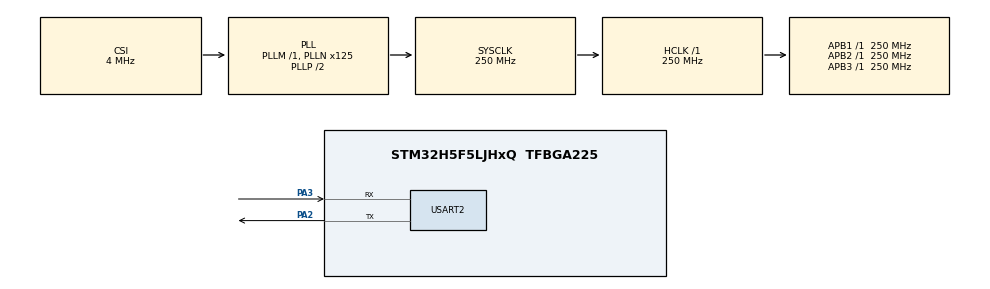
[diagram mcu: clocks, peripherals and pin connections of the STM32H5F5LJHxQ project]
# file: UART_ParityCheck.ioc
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CORTEX_M33_NS.userName=CORTEX_M33
Mcu.Family=STM32H5
Mcu.Name=STM32H5F5LJHxQ
Mcu.Package=TFBGA225
NVIC.PriorityGroup=NVIC_PRIORITYGROUP_4
NVIC.USART2_IRQn=true\:0\:0\:false\:false\:true\:true\:true\:true
PA2.Mode=Asynchronous
PA2.Signal=USART2_TX
PA3.Mode=Asynchronous
PA3.Signal=USART2_RX
ProjectManager.HeapSize=0x200
ProjectManager.StackSize=0x400
ProjectManager.TargetToolchain=EWARM V9.20
RCC.ADCFreq_Value=250000000
RCC.AHBFreq_Value=250000000
RCC.APB1Freq_Value=250000000
RCC.APB1TimFreq_Value=250000000
RCC.APB2Freq_Value=250000000
RCC.APB2TimFreq_Value=250000000
RCC.APB3Freq_Value=250000000
RCC.CSI_VALUE=4000000
RCC.CortexFreq_Value=250000000
RCC.EPOD_VALUE=4000000
RCC.HCLKFreq_Value=250000000
RCC.HSE_VALUE=25000000
RCC.HSI48_VALUE=48000000
RCC.HSI_VALUE=64000000
RCC.LSE_VALUE=32768
RCC.LSIRC_VALUE=32000
RCC.PLLN=125
RCC.SYSCLKFreq_VALUE=250000000
RCC.SYSCLKSource=RCC_SYSCLKSOURCE_PLLCLK
RCC.USBFreq_Value=258000000
RCC.VCOOutputFreq_Value=500000000
USART2.Parity=PARITY_ODD
USART2.VirtualMode-Asynchronous=VM_ASYNC
USART2.WordLength=WORDLENGTH_9B
VP_CORTEX_M33_NS_VS_Hclk.Mode=Hclk_Mode
VP_ICACHE_VS_ICACHE.Mode=DefaultMode
VP_PWR_VS_LPOM.Mode=PowerOptimisation
VP_PWR_VS_SECSignals.Mode=Security/Privilege
board=custom

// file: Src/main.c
/* USER CODE BEGIN Header */
/**
  ******************************************************************************
  * @file    UART/UART_ParityCheck/Src/main.c
  * @author  MCD Application Team
  * @brief   This example shows how to retarget the C library printf function
  *          to the UART.
  ******************************************************************************
  * @attention
  *
  * Copyright (c) 2023 STMicroelectronics.
  * All rights reserved.
  *
  * This software is licensed under terms that can be found in the LICENSE file
  * in the root directory of this software component.
  * If no LICENSE file comes with this software, it is provided AS-IS.
  *
  ******************************************************************************
  */
/* USER CODE END Header */
#include "main.h"

UART_HandleTypeDef huart2;

/* USER CODE BEGIN PV */
uint8_t aTxStartMessage[] = "\n\r ****UART-ParityCheck communication based on IT ****\n\r Enter 10 characters using keyboard :\n\r";
uint8_t aTxParityErrorMessage[] = "\n\r Parity error detected, parity is now set to even. Please retry sending 10 characters \n\r";
uint8_t aTxEndMessage[] = "\n\r No Parity error detected, end of example \n\r";

/* Buffer used for reception */
uint8_t aRxBuffer[RXBUFFERSIZE];

volatile uint8_t Parity_Error_Count = 0U;
volatile uint8_t TxCpltCallback = 0U;
volatile uint8_t RxCpltCallback = 0U;
/* USER CODE END PV */

void SystemClock_Config(void);
static void MX_GPIO_Init(void);
static void MX_ICACHE_Init(void);
static void MX_USART2_UART_Init(void);

int main(void)
{

  /* USER CODE BEGIN 1 */

  /* STM32H5xx HAL library initialization:
       - Systick timer is configured by default as source of time base, but user
             can eventually implement his proper time base source (a general purpose
             timer for example or other time source), keeping in mind that Time base
             duration should be kept 1ms since PPP_TIMEOUT_VALUEs are defined and
             handled in milliseconds basis.
       - Set NVIC Group Priority to 4
       - Low Level Initialization
     */
  /* USER CODE END 1 */

  /* MCU Configuration--------------------------------------------------------*/

  /* Reset of all peripherals, Initializes the Flash interface and the Systick. */
  HAL_Init();

  /* Configure the system clock */
  SystemClock_Config();

  /* USER CODE BEGIN SysInit */
  /* Initialize BSP Led for LED3 & LED1 */
  BSP_LED_Init(LED3);
  BSP_LED_Init(LED1);

  /* USER CODE END SysInit */

  /* Initialize all configured peripherals */
  MX_GPIO_Init();
  MX_ICACHE_Init();
  MX_USART2_UART_Init();
  /* USER CODE BEGIN 2 */

  /*##-1- Start the transmission process ######################################*/
  if(HAL_UART_Transmit_IT(&huart2, (uint8_t*)aTxStartMessage, TXSTARTMESSAGESIZE)!= HAL_OK)
  {
    /* Transfer error in transmission process */
    Error_Handler();
  }

  /*##-2- Wait for the end of the transfer ####################################*/
  /*  As the next step is to change the parity to create a parity error
      in the next reception, we need to make sure the last transfer ended
      before changing the configuration */
  while (TxCpltCallback == 0U)
  {
  }
  TxCpltCallback = 0U;

  /*##-3- Change Parity configuration to trigger a parity error ###############*/
  huart2.Init.Parity = UART_PARITY_EVEN;
  if (HAL_UART_Init(&huart2) != HAL_OK)
  {
    Error_Handler();
  }

  /*##-4- Put UART peripheral in reception process ############################*/
  /* Any data received will be stored in "aRxBuffer" buffer : the number max of
     data received is 10 */
  if(HAL_UART_Receive_IT(&huart2, (uint8_t *)aRxBuffer, RXBUFFERSIZE) != HAL_OK)
  {
    /* Transfer error in reception process */
    Error_Handler();
  }

  /*##-5- Wait for the end of the transfer ####################################*/
  /* After detecting a parity error the HAL_UART_ErrorCallback will update the
    private variable Parity_Error_Count to reflect the error status. This variable is
    then used in main to change the parity configuration once the reception is completed,
    thus we make sure to avoid starting the next transfer before the parity configuration change */
  while (RxCpltCallback == 0U)
  {
  }
  RxCpltCallback = 0U;

  /* Each character received triggers a parity error */
  if (Parity_Error_Count == RXBUFFERSIZE)
  {
    /* Parity error detected */
    BSP_LED_On(LED1);

    /*##-6- Change back parity configuration ##################################*/
    huart2.Init.Parity = UART_PARITY_ODD;
    if (HAL_UART_Init(&huart2) != HAL_OK)
    {
      Error_Handler();
    }

    /*##-7- Send the Error message ############################################*/
    if(HAL_UART_Transmit_IT(&huart2, (uint8_t*)aTxParityErrorMessage, TXPARITYERRORMESSAGESIZE)!= HAL_OK)
    {
      /* Transfer error in transmission process */
      Error_Handler();
    }

    /*##-8- Put UART peripheral in reception process ##########################*/
    /* Any data received will be stored in "aRxBuffer" buffer : the number max of
       data received is 10 */
    if(HAL_UART_Receive_IT(&huart2, (uint8_t *)aRxBuffer, RXBUFFERSIZE) != HAL_OK)
    {
      /* Transfer error in reception process */
      Error_Handler();
    }

    /*##-9- Wait for the end of the transfer ##################################*/
    while ((TxCpltCallback == 0U) || (RxCpltCallback == 0U))
    {
    }
    TxCpltCallback = 0U;
    RxCpltCallback = 0U;
  }
  else
  {
    /*Parity error should have been detected, please check your terminal configuration*/
    Error_Handler();
  }

   /*##-10- Send the received Buffer ##########################################*/
  if(HAL_UART_Transmit_IT(&huart2, (uint8_t*)aRxBuffer, RXBUFFERSIZE)!= HAL_OK)
  {
    /* Transfer error in transmission process */
    Error_Handler();
  }

  /*##-11- Wait for the end of the transfer ###################################*/
  while (TxCpltCallback == 0U)
  {
  }
  TxCpltCallback = 0U;

  /*##-12- Send the End Message ###############################################*/
  if(HAL_UART_Transmit_IT(&huart2, (uint8_t*)aTxEndMessage, TXENDMESSAGESIZE)!= HAL_OK)
  {
    /* Transfer error in transmission process */
    Error_Handler();
  }

  /*##-13- Wait for the end of the transfer ###################################*/
  while (TxCpltCallback == 0U)
  {
  }
  TxCpltCallback = 0U;

  /* Turn on LED3 and off LED1 if test passes then enter infinite loop */
  BSP_LED_On(LED3);
  BSP_LED_Off(LED1);
  /* USER CODE END 2 */

  /* Infinite loop */
  while (1)
  {

  }
}

void SystemClock_Config(void)
{
  RCC_OscInitTypeDef RCC_OscInitStruct = {0};
  RCC_ClkInitTypeDef RCC_ClkInitStruct = {0};

  /** Configure the main internal regulator output voltage
  */
  __HAL_PWR_VOLTAGESCALING_CONFIG(PWR_REGULATOR_VOLTAGE_SCALE0);

  while(!__HAL_PWR_GET_FLAG(PWR_FLAG_VOSRDY)) {}

  /** Initializes the RCC Oscillators according to the specified parameters
  * in the RCC_OscInitTypeDef structure.
  */
  RCC_OscInitStruct.OscillatorType = RCC_OSCILLATORTYPE_CSI;
  RCC_OscInitStruct.CSIState = RCC_CSI_ON;
  RCC_OscInitStruct.CSICalibrationValue = RCC_CSICALIBRATION_DEFAULT;
  RCC_OscInitStruct.PLL.PLLState = RCC_PLL_ON;
  RCC_OscInitStruct.PLL.PLLSource = RCC_PLL1_SOURCE_CSI;
  RCC_OscInitStruct.PLL.PLLM = 1;
  RCC_OscInitStruct.PLL.PLLN = 125;
  RCC_OscInitStruct.PLL.PLLP = 2;
  RCC_OscInitStruct.PLL.PLLQ = 2;
  RCC_OscInitStruct.PLL.PLLR = 2;
  RCC_OscInitStruct.PLL.PLLRGE = RCC_PLL1_VCIRANGE_2;
  RCC_OscInitStruct.PLL.PLLVCOSEL = RCC_PLL1_VCORANGE_WIDE;
  RCC_OscInitStruct.PLL.PLLFRACN = 0;
  if (HAL_RCC_OscConfig(&RCC_OscInitStruct) != HAL_OK)
  {
    Error_Handler();
  }

  /** Initializes the CPU, AHB and APB buses clocks
  */
  RCC_ClkInitStruct.ClockType = RCC_CLOCKTYPE_HCLK|RCC_CLOCKTYPE_SYSCLK
                              |RCC_CLOCKTYPE_PCLK1|RCC_CLOCKTYPE_PCLK2
                              |RCC_CLOCKTYPE_PCLK3;
  RCC_ClkInitStruct.SYSCLKSource = RCC_SYSCLKSOURCE_PLLCLK;
  RCC_ClkInitStruct.AHBCLKDivider = RCC_SYSCLK_DIV1;
  RCC_ClkInitStruct.APB1CLKDivider = RCC_HCLK_DIV1;
  RCC_ClkInitStruct.APB2CLKDivider = RCC_HCLK_DIV1;
  RCC_ClkInitStruct.APB3CLKDivider = RCC_HCLK_DIV1;

  if (HAL_RCC_ClockConfig(&RCC_ClkInitStruct, FLASH_LATENCY_5) != HAL_OK)
  {
    Error_Handler();
  }

  /** Configure the programming delay
  */
  __HAL_FLASH_SET_PROGRAM_DELAY(FLASH_PROGRAMMING_DELAY_2);
}

static void MX_ICACHE_Init(void)
{

  /** Enable instruction cache (default 2-ways set associative cache)
  */
  if (HAL_ICACHE_Enable() != HAL_OK)
  {
    Error_Handler();
  }

}

static void MX_USART2_UART_Init(void)
{

  huart2.Instance = USART2;
  huart2.Init.BaudRate = 115200;
  huart2.Init.WordLength = UART_WORDLENGTH_9B;
  huart2.Init.StopBits = UART_STOPBITS_1;
  huart2.Init.Parity = UART_PARITY_ODD;
  huart2.Init.Mode = UART_MODE_TX_RX;
  huart2.Init.HwFlowCtl = UART_HWCONTROL_NONE;
  huart2.Init.OverSampling = UART_OVERSAMPLING_16;
  huart2.Init.OneBitSampling = UART_ONE_BIT_SAMPLE_DISABLE;
  huart2.Init.ClockPrescaler = UART_PRESCALER_DIV1;
  huart2.AdvancedInit.AdvFeatureInit = UART_ADVFEATURE_NO_INIT;
  if (HAL_UART_Init(&huart2) != HAL_OK)
  {
    Error_Handler();
  }
  if (HAL_UARTEx_SetTxFifoThreshold(&huart2, UART_TXFIFO_THRESHOLD_1_8) != HAL_OK)
  {
    Error_Handler();
  }
  if (HAL_UARTEx_SetRxFifoThreshold(&huart2, UART_RXFIFO_THRESHOLD_1_8) != HAL_OK)
  {
    Error_Handler();
  }
  if (HAL_UARTEx_DisableFifoMode(&huart2) != HAL_OK)
  {
    Error_Handler();
  }

}

static void MX_GPIO_Init(void)
{

}

/* USER CODE BEGIN 4 */

/**
  * @brief  Tx Transfer completed callback
  * @param  UartHandle: UART handle.
  * @note   This example shows a simple way to report end of IT Tx transfer, and
  *         you can add your own implementation.
  * @retval None
  */
void HAL_UART_TxCpltCallback(UART_HandleTypeDef *UartHandle)
{
  TxCpltCallback++;
}

/**
  * @brief  Rx Transfer completed callback
  * @param  UartHandle: UART handle
  * @note   This example shows a simple way to report end of IT Rx transfer, and
  *         you can add your own implementation.
  * @retval None
  */
void HAL_UART_RxCpltCallback(UART_HandleTypeDef *UartHandle)
{
  RxCpltCallback++;
}

/**
  * @brief  UART error callbacks
  * @param  UartHandle: UART handle
  * @note   This example shows a simple way to report transfer error, and you can
  *         add your own implementation.
  * @retval None
  */
void HAL_UART_ErrorCallback(UART_HandleTypeDef *UartHandle)
{
  if ((huart2.ErrorCode & HAL_UART_ERROR_PE) != 0U)
  {
    /* In case of parity error */
    Parity_Error_Count++;

    /* Parity error code clear*/
    huart2.ErrorCode = (huart2.ErrorCode & (~HAL_UART_ERROR_PE));
  }
}

/* USER CODE END 4 */

void Error_Handler(void)
{
  /* USER CODE BEGIN Error_Handler_Debug */
  /* User can add his own implementation to report the HAL error return state */
  while (1)
  {
    /* Toggle LED1 for error */
    BSP_LED_Toggle(LED1);
    HAL_Delay(500);
  }

  /* USER CODE END Error_Handler_Debug */
}
